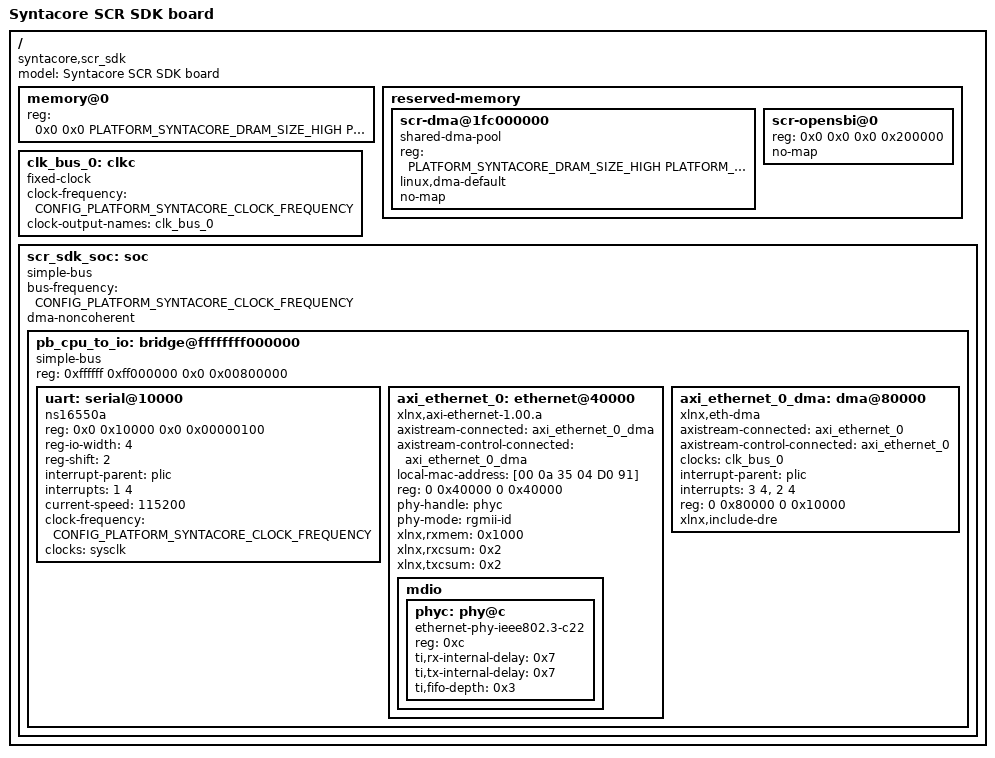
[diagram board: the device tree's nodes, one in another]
/*
 * Copyright (C) 2016, Syntacore Ltd.
 *
 * Redistribution and use in source and binary forms, with or without
 * modification, are permitted provided that the following conditions are met:
 *     1. Redistributions of source code must retain the above copyright notice,
 *        this list of conditions and the following disclaimer.
 *     2. Redistributions in binary form must reproduce the above copyright
 *        notice, this list of conditions and the following disclaimer in the
 *        documentation and/or other materials provided with the distribution.
 *     3. Neither the name of the copyright holder nor the names of its
 *        contributors may be used to endorse or promote products derived from
 *        this software without specific prior written permission.
 *
 * THIS SOFTWARE IS PROVIDED BY THE COPYRIGHT HOLDERS AND CONTRIBUTORS "AS IS" AND
 * ANY EXPRESS OR IMPLIED WARRANTIES, INCLUDING, BUT NOT LIMITED TO, THE IMPLIED
 * WARRANTIES OF MERCHANTABILITY AND FITNESS FOR A PARTICULAR PURPOSE ARE
 * DISCLAIMED. IN NO EVENT SHALL THE COPYRIGHT HOLDER OR CONTRIBUTORS BE LIABLE
 * FOR ANY DIRECT, INDIRECT, INCIDENTAL, SPECIAL, EXEMPLARY, OR CONSEQUENTIAL
 * DAMAGES (INCLUDING, BUT NOT LIMITED TO, PROCUREMENT OF SUBSTITUTE GOODS OR
 * SERVICES; LOSS OF USE, DATA, OR PROFITS; OR BUSINESS INTERRUPTION) HOWEVER
 * CAUSED AND ON ANY THEORY OF LIABILITY, WHETHER IN CONTRACT, STRICT LIABILITY,
 * OR TORT (INCLUDING NEGLIGENCE OR OTHERWISE) ARISING IN ANY WAY OUT OF THE USE
 * OF THIS SOFTWARE, EVEN IF ADVISED OF THE POSSIBILITY OF SUCH DAMAGE.
 */

#include "scr_sdk_convert.h"

/ {
	model = "Syntacore SCR SDK board";
	compatible = "syntacore,scr_sdk";
	#address-cells = <2>;
	#size-cells = <2>;

	memory@0 {
		#address-cells = <2>;
		#size-cells = <2>;
		device_type = "memory";
		reg = <0x0 0x0 PLATFORM_SYNTACORE_DRAM_SIZE_HIGH PLATFORM_SYNTACORE_DRAM_SIZE_LOW>;
	};

	reserved-memory {
		#address-cells = <2>;
		#size-cells = <2>;
		ranges;

		scr-dma@1fc000000 {
			reg = <PLATFORM_SYNTACORE_DRAM_SIZE_HIGH PLATFORM_SYNTACORE_DRAM_SIZE_LOW 0 PLATFORM_SYNTACORE_DMA_SIZE>;
			compatible = "shared-dma-pool";
			linux,dma-default;
			no-map;
		};

		scr-opensbi@0 {
			reg = <0x0 0x0 0x0 0x200000>;
			no-map;
		};
	};

	clk_bus_0: clkc {
		#clock-cells = <0>;
		clock-frequency = <CONFIG_PLATFORM_SYNTACORE_CLOCK_FREQUENCY>;
		clock-output-names = "clk_bus_0";
		compatible = "fixed-clock";
	};

	scr_sdk_soc: soc {
		device_type = "soc";
		ranges;
		#address-cells = <2>;
		#size-cells = <2>;
		compatible = "simple-bus";
		bus-frequency = <CONFIG_PLATFORM_SYNTACORE_CLOCK_FREQUENCY>;
		dma-noncoherent;
	};
};

&scr_sdk_soc {
	#address-cells = <2>;
	#size-cells = <2>;

	pb_cpu_to_io: bridge@ffffffff000000 {
		compatible = "simple-bus";
		reg = <0xffffff 0xff000000 0x0 0x00800000>;
		#address-cells = <2>;
		#size-cells = <2>;
		ranges = <0x0 0x0 0xffffff 0xff000000 0x0 0x00800000>;

		uart: serial@10000 {
			compatible = "ns16550a";
			reg = <0x0 0x10000 0x0 0x00000100>;
			reg-io-width = <4>;
			reg-shift = <2>;
			interrupt-parent = <&plic>;
			interrupts = <1 4>;
			current-speed = <115200>;
			clock-frequency = <CONFIG_PLATFORM_SYNTACORE_CLOCK_FREQUENCY>;
			clocks = <&sysclk>;
		};

		axi_ethernet_0: ethernet@40000 {
			axistream-connected = <&axi_ethernet_0_dma>;
			axistream-control-connected = <&axi_ethernet_0_dma>;

			compatible = "xlnx,axi-ethernet-1.00.a";
			device_type = "network";
			local-mac-address = [00 0a 35 04 D0 91];

			reg = <0 0x40000 0 0x40000>;

			phy-handle = <&phyc>;
			phy-mode = "rgmii-id";

			xlnx,rxmem = <0x1000>;
			xlnx,rxcsum = <0x2>;
			xlnx,txcsum = <0x2>;

			mdio {
				#address-cells = <1>;
				#size-cells = <0>;

				phyc: phy@c {
					compatible = "ethernet-phy-ieee802.3-c22";
					reg = <0xc>;
					ti,rx-internal-delay = <0x7>;
					ti,tx-internal-delay = <0x7>;
					ti,fifo-depth = <0x3>;
				};
			};
		};

		axi_ethernet_0_dma: dma@80000 {
			#dma-cells = <1>;
			axistream-connected = <&axi_ethernet_0>;
			axistream-control-connected = <&axi_ethernet_0>;
			clock-names = "s_axi_lite_aclk";
			clocks = <&clk_bus_0>;
			compatible = "xlnx,eth-dma";
			interrupt-parent = <&plic>;
			interrupts = <3 4>,<2 4>;
			reg = <0 0x80000 0 0x10000>;
			xlnx,include-dre;
		};
	};
};
